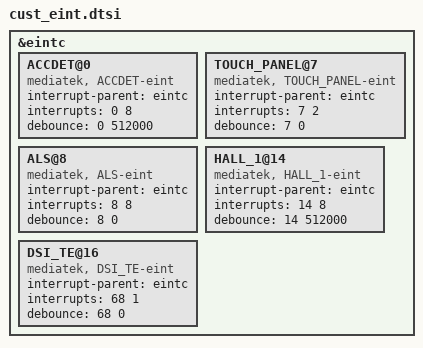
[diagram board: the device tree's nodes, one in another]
/*
 * Generated by MTK SP Drv_CodeGen Version 03.13.6  for MT6580. Copyright MediaTek Inc. (C) 2013.
 * Mon May  8 18:40:44 2017
 * Do Not Modify the File.
 */

/*************************
 * EINT DTSI File
*************************/

&eintc {
	ACCDET@0 {
		compatible = "mediatek, ACCDET-eint";
		interrupt-parent = <&eintc>;
		interrupts = <0 8>;
		debounce = <0 512000>;
	};

	TOUCH_PANEL@7 {
		compatible = "mediatek, TOUCH_PANEL-eint";
		interrupt-parent = <&eintc>;
		interrupts = <7 2>;
		debounce = <7 0>;
	};

	ALS@8 {
		compatible = "mediatek, ALS-eint";
		interrupt-parent = <&eintc>;
		interrupts = <8 8>;
		debounce = <8 0>;
	};

	HALL_1@14 {
		compatible = "mediatek, HALL_1-eint";
		interrupt-parent = <&eintc>;
		interrupts = <14 8>;
		debounce = <14 512000>;
	};

	DSI_TE@16 {
		compatible = "mediatek, DSI_TE-eint";
		interrupt-parent = <&eintc>;
		interrupts = <68 1>;
		debounce = <68 0>;
	};

};
